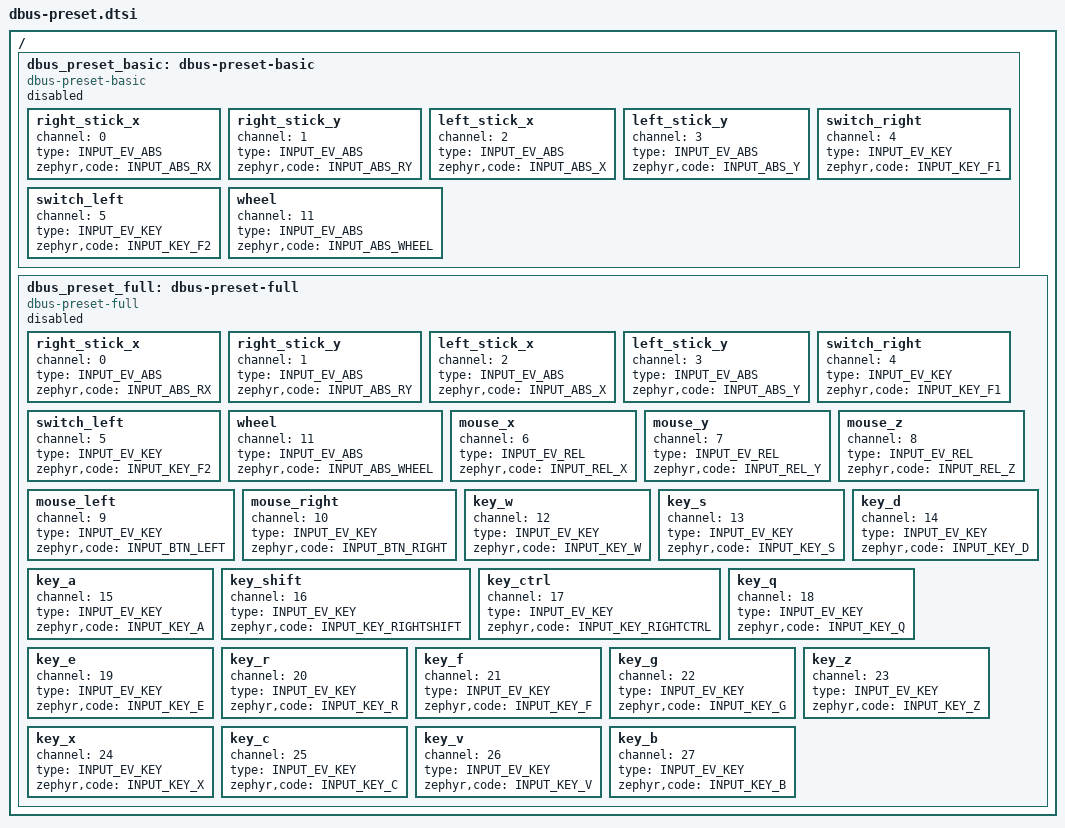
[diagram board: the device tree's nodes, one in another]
/*
 * Copyright (c) 2025 MoonFeather
 * SPDX-License-Identifier: BSD-3-Clause
 */

#include <dt-bindings/input/input-event-codes.h>

/ {
	dbus_preset_basic: dbus-preset-basic {
		compatible = "dbus-preset-basic";
		status = "disabled";

		right_stick_x {
			channel = <0>;
			type = <INPUT_EV_ABS>;
			zephyr,code = <INPUT_ABS_RX>;
		};
		right_stick_y {
			channel = <1>;
			type = <INPUT_EV_ABS>;
			zephyr,code = <INPUT_ABS_RY>;
		};
		left_stick_x {
			channel = <2>;
			type = <INPUT_EV_ABS>;
			zephyr,code = <INPUT_ABS_X>;
		};
		left_stick_y {
			channel = <3>;
			type = <INPUT_EV_ABS>;
			zephyr,code = <INPUT_ABS_Y>;
		};
		switch_right {
			channel = <4>;
			type = <INPUT_EV_KEY>;
			zephyr,code = <INPUT_KEY_F1>;
		};
		switch_left {
			channel = <5>;
			type = <INPUT_EV_KEY>;
			zephyr,code = <INPUT_KEY_F2>;
		};
		wheel {
			channel = <11>;
			type = <INPUT_EV_ABS>;
			zephyr,code = <INPUT_ABS_WHEEL>;
		};
	};

	dbus_preset_full: dbus-preset-full {
		compatible = "dbus-preset-full";
		status = "disabled";

		right_stick_x {
			channel = <0>;
			type = <INPUT_EV_ABS>;
			zephyr,code = <INPUT_ABS_RX>;
		};
		right_stick_y {
			channel = <1>;
			type = <INPUT_EV_ABS>;
			zephyr,code = <INPUT_ABS_RY>;
		};
		left_stick_x {
			channel = <2>;
			type = <INPUT_EV_ABS>;
			zephyr,code = <INPUT_ABS_X>;
		};
		left_stick_y {
			channel = <3>;
			type = <INPUT_EV_ABS>;
			zephyr,code = <INPUT_ABS_Y>;
		};
		switch_right {
			channel = <4>;
			type = <INPUT_EV_KEY>;
			zephyr,code = <INPUT_KEY_F1>;
		};
		switch_left {
			channel = <5>;
			type = <INPUT_EV_KEY>;
			zephyr,code = <INPUT_KEY_F2>;
		};
		wheel {
			channel = <11>;
			type = <INPUT_EV_ABS>;
			zephyr,code = <INPUT_ABS_WHEEL>;
		};

		mouse_x {
			channel = <6>;
			type = <INPUT_EV_REL>;
			zephyr,code = <INPUT_REL_X>;
		};
		mouse_y {
			channel = <7>;
			type = <INPUT_EV_REL>;
			zephyr,code = <INPUT_REL_Y>;
		};
		mouse_z {
			channel = <8>;
			type = <INPUT_EV_REL>;
			zephyr,code = <INPUT_REL_Z>;
		};
		mouse_left {
			channel = <9>;
			type = <INPUT_EV_KEY>;
			zephyr,code = <INPUT_BTN_LEFT>;
		};
		mouse_right {
			channel = <10>;
			type = <INPUT_EV_KEY>;
			zephyr,code = <INPUT_BTN_RIGHT>;
		};
		key_w {
			channel = <12>;
			type = <INPUT_EV_KEY>;
			zephyr,code = <INPUT_KEY_W>;
		};
		key_s {
			channel = <13>;
			type = <INPUT_EV_KEY>;
			zephyr,code = <INPUT_KEY_S>;
		};
		key_d {
			channel = <14>;
			type = <INPUT_EV_KEY>;
			zephyr,code = <INPUT_KEY_D>;
		};
		key_a {
			channel = <15>;
			type = <INPUT_EV_KEY>;
			zephyr,code = <INPUT_KEY_A>;
		};
		key_shift {
			channel = <16>;
			type = <INPUT_EV_KEY>;
			zephyr,code = <INPUT_KEY_RIGHTSHIFT>;
		};
		key_ctrl {
			channel = <17>;
			type = <INPUT_EV_KEY>;
			zephyr,code = <INPUT_KEY_RIGHTCTRL>;
		};
		key_q {
			channel = <18>;
			type = <INPUT_EV_KEY>;
			zephyr,code = <INPUT_KEY_Q>;
		};
		key_e {
			channel = <19>;
			type = <INPUT_EV_KEY>;
			zephyr,code = <INPUT_KEY_E>;
		};
		key_r {
			channel = <20>;
			type = <INPUT_EV_KEY>;
			zephyr,code = <INPUT_KEY_R>;
		};
		key_f {
			channel = <21>;
			type = <INPUT_EV_KEY>;
			zephyr,code = <INPUT_KEY_F>;
		};
		key_g {
			channel = <22>;
			type = <INPUT_EV_KEY>;
			zephyr,code = <INPUT_KEY_G>;
		};
		key_z {
			channel = <23>;
			type = <INPUT_EV_KEY>;
			zephyr,code = <INPUT_KEY_Z>;
		};
		key_x {
			channel = <24>;
			type = <INPUT_EV_KEY>;
			zephyr,code = <INPUT_KEY_X>;
		};
		key_c {
			channel = <25>;
			type = <INPUT_EV_KEY>;
			zephyr,code = <INPUT_KEY_C>;
		};
		key_v {
			channel = <26>;
			type = <INPUT_EV_KEY>;
			zephyr,code = <INPUT_KEY_V>;
		};
		key_b {
			channel = <27>;
			type = <INPUT_EV_KEY>;
			zephyr,code = <INPUT_KEY_B>;
		};
	};
};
